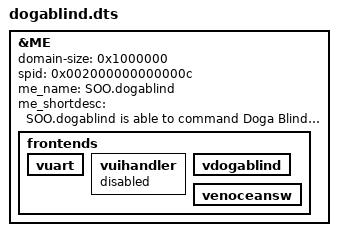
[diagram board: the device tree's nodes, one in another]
/*
 * Copyright (C) 2016-2018 Thomas Rieder <thomas.rieder@heig-vd.ch>
 *
 * This program is free software; you can redistribute it and/or modify
 * it under the terms of the GNU General Public License version 2 as
 * published by the Free Software Foundation.
 *
 * This program is distributed in the hope that it will be useful,
 * but WITHOUT ANY WARRANTY; without even the implied warranty of
 * MERCHANTABILITY or FITNESS FOR A PARTICULAR PURPOSE.  See the
 * GNU General Public License for more details.
 *
 * You should have received a copy of the GNU General Public License
 * along with this program; if not, write to the Free Software
 * Foundation, Inc., 51 Franklin St, Fifth Floor, Boston, MA  02110-1301  USA
 *
 */

/dts-v1/;

#include "so3virt.dtsi"

&ME {
	/* 4 MB is enough */
	domain-size = <0x1000000>;
	
	/* SPID on 128-bit encoding */
	spid = /bits/ 64 <0x002000000000000c>;
		
	/* Name of this ME */
	me_name = "SOO.dogablind";
		
	/* Short description */
	me_shortdesc =
			
"SOO.dogablind is able to command Doga Blind and receive command from EnOcean switch";

	frontends {
		/* Enabling the console */
		vuart {
			status = "ok";
		};

		vuihandler {
			status = "disabled";
		};
	
		vdogablind {
			status = "ok";
		};
		
		venoceansw {
			status = "ok";
		};
	};
};
	
